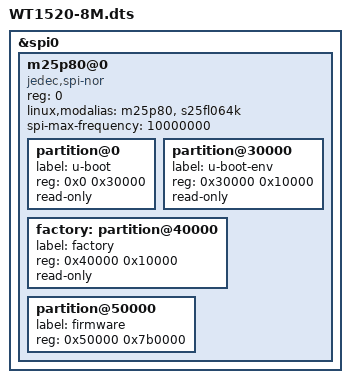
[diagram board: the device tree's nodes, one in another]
/dts-v1/;

#include "WT1520.dtsi"

&spi0 {
	status = "okay";

	m25p80@0 {
		#address-cells = <1>;
		#size-cells = <1>;
		compatible = "jedec,spi-nor";
		reg = <0>;
		linux,modalias = "m25p80", "s25fl064k";
		spi-max-frequency = <10000000>;

		partition@0 {
			label = "u-boot";
			reg = <0x0 0x30000>;
			read-only;
		};

		partition@30000 {
			label = "u-boot-env";
			reg = <0x30000 0x10000>;
			read-only;
		};

		factory: partition@40000 {
			label = "factory";
			reg = <0x40000 0x10000>;
			read-only;
		};

		partition@50000 {
			label = "firmware";
			reg = <0x50000 0x7b0000>;
		};
	};
};
